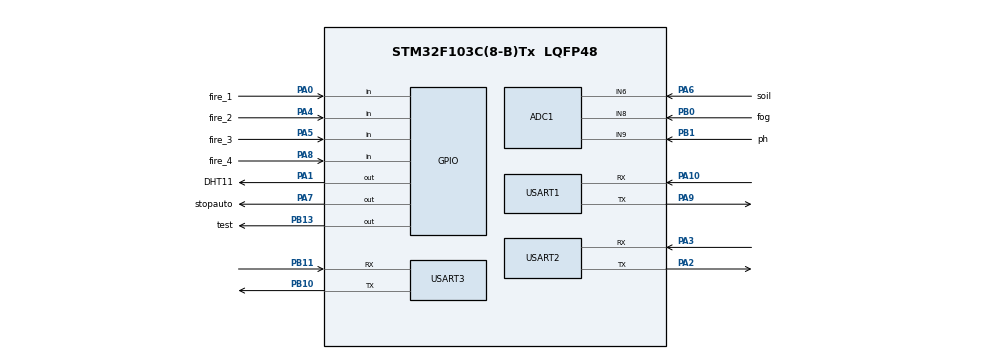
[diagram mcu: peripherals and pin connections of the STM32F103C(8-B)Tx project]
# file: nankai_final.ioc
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ADC1.Channel-0\#ChannelRegularConversion=ADC_CHANNEL_9
ADC1.NbrOfConversionFlag=1
ADC1.Rank-0\#ChannelRegularConversion=1
ADC1.SamplingTime-0\#ChannelRegularConversion=ADC_SAMPLETIME_1CYCLE_5
ADC1.master=1
Mcu.Family=STM32F1
Mcu.Name=STM32F103C(8-B)Tx
Mcu.Package=LQFP48
NVIC.PriorityGroup=NVIC_PRIORITYGROUP_4
NVIC.RCC_IRQn=true\:0\:0\:false\:false\:true\:true\:false\:true
NVIC.USART1_IRQn=true\:0\:0\:false\:false\:true\:true\:true\:true
NVIC.USART2_IRQn=true\:0\:0\:false\:false\:true\:true\:true\:true
PA0-WKUP.GPIO_Label=fire_1
PA0-WKUP.Signal=GPIO_Input
PA1.GPIO_Label=DHT11
PA1.Signal=GPIO_Output
PA10.Mode=Asynchronous
PA10.Signal=USART1_RX
PA13.Mode=Serial_Wire
PA13.Signal=SYS_JTMS-SWDIO
PA14.Mode=Serial_Wire
PA14.Signal=SYS_JTCK-SWCLK
PA2.Mode=Asynchronous
PA2.Signal=USART2_TX
PA3.Mode=Asynchronous
PA3.Signal=USART2_RX
PA4.GPIO_Label=fire_2
PA4.Signal=GPIO_Input
PA5.GPIO_Label=fire_3
PA5.Signal=GPIO_Input
PA6.GPIO_Label=soil
PA6.Signal=ADCx_IN6
PA7.GPIO_Label=stopauto
PA7.Signal=GPIO_Output
PA8.GPIO_Label=fire_4
PA8.Signal=GPIO_Input
PA9.Mode=Asynchronous
PA9.Signal=USART1_TX
PB0.GPIO_Label=fog
PB0.Signal=ADCx_IN8
PB1.GPIO_Label=ph
PB1.Signal=ADCx_IN9
PB10.Mode=Asynchronous
PB10.Signal=USART3_TX
PB11.Mode=Asynchronous
PB11.Signal=USART3_RX
PB13.GPIO_Label=test
PB13.Signal=GPIO_Output
PD0-OSC_IN.Mode=HSE-External-Oscillator
PD0-OSC_IN.Signal=RCC_OSC_IN
PD1-OSC_OUT.Mode=HSE-External-Oscillator
PD1-OSC_OUT.Signal=RCC_OSC_OUT
ProjectManager.HeapSize=0x200
ProjectManager.StackSize=0x400
ProjectManager.TargetToolchain=MDK-ARM V5
RCC.APB1Freq_Value=8000000
RCC.APB2Freq_Value=8000000
SH.ADCx_IN6.0=ADC1_IN6,IN6
SH.ADCx_IN8.0=ADC1_IN8,IN8
SH.ADCx_IN9.0=ADC1_IN9,IN9
USART1.VirtualMode=VM_ASYNC
USART2.VirtualMode=VM_ASYNC
USART3.VirtualMode=VM_ASYNC
board=custom

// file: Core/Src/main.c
/* USER CODE BEGIN Header */
/**
  ******************************************************************************
  * @file           : main.c
  * @brief          : Main program body
  ******************************************************************************
  * @attention
  *
  * Copyright (c) 2025 STMicroelectronics.
  * All rights reserved.
  *
  * This software is licensed under terms that can be found in the LICENSE file
  * in the root directory of this software component.
  * If no LICENSE file comes with this software, it is provided AS-IS.
  *
  ******************************************************************************
  */
/* USER CODE END Header */
#include "main.h"
#include "adc.h"
#include "usart.h"
#include "gpio.h"

/* USER CODE BEGIN Includes */
#include "sensors.h"
#include <stdio.h>
#include <string.h>
/* USER CODE END Includes */

/* USER CODE BEGIN PV */
uint32_t sensorTimer = 0; // 传感器定时器计数
/* USER CODE END PV */

void SystemClock_Config(void);

int main(void)
{

  /* MCU Configuration--------------------------------------------------------*/

  /* Reset of all peripherals, Initializes the Flash interface and the Systick. */
  HAL_Init();

  /* Configure the system clock */
  SystemClock_Config();

  /* Initialize all configured peripherals */
  MX_GPIO_Init();
  MX_ADC1_Init();
  MX_USART1_UART_Init();
  MX_USART2_UART_Init();
  MX_USART3_UART_Init();
  /* USER CODE BEGIN 2 */

  // 初始化传感器
  Sensors_Init();

  // 发�?�启动消�?
  char startup_msg[] = "STM32 Sensor System Started\r\n";
  HAL_UART_Transmit(&huart1, (uint8_t*)startup_msg, strlen(startup_msg), 100);

  // 获取初始传感器数据并发�??
  Sensors_SendDataToUSART3();

  // 初始化定时器
  sensorTimer = HAL_GetTick();

  /* USER CODE END 2 */

  /* Infinite loop */
  while (1)
  {

    /* USER CODE BEGIN 3 */

    // �?1000ms(1�?)读取�?次传感器数据并发�?
    if (HAL_GetTick() - sensorTimer >= 1000)
    {
      // 获取并发送所有传感器数据
      Sensors_TimerHandler();

      // 更新定时�?
      sensorTimer = HAL_GetTick();
    }

  }
  /* USER CODE END 3 */
}

void SystemClock_Config(void)
{
  RCC_OscInitTypeDef RCC_OscInitStruct = {0};
  RCC_ClkInitTypeDef RCC_ClkInitStruct = {0};
  RCC_PeriphCLKInitTypeDef PeriphClkInit = {0};

  /** Initializes the RCC Oscillators according to the specified parameters
  * in the RCC_OscInitTypeDef structure.
  */
  RCC_OscInitStruct.OscillatorType = RCC_OSCILLATORTYPE_HSI;
  RCC_OscInitStruct.HSIState = RCC_HSI_ON;
  RCC_OscInitStruct.HSICalibrationValue = RCC_HSICALIBRATION_DEFAULT;
  RCC_OscInitStruct.PLL.PLLState = RCC_PLL_NONE;
  if (HAL_RCC_OscConfig(&RCC_OscInitStruct) != HAL_OK)
  {
    Error_Handler();
  }

  /** Initializes the CPU, AHB and APB buses clocks
  */
  RCC_ClkInitStruct.ClockType = RCC_CLOCKTYPE_HCLK|RCC_CLOCKTYPE_SYSCLK
                              |RCC_CLOCKTYPE_PCLK1|RCC_CLOCKTYPE_PCLK2;
  RCC_ClkInitStruct.SYSCLKSource = RCC_SYSCLKSOURCE_HSI;
  RCC_ClkInitStruct.AHBCLKDivider = RCC_SYSCLK_DIV1;
  RCC_ClkInitStruct.APB1CLKDivider = RCC_HCLK_DIV1;
  RCC_ClkInitStruct.APB2CLKDivider = RCC_HCLK_DIV1;

  if (HAL_RCC_ClockConfig(&RCC_ClkInitStruct, FLASH_LATENCY_0) != HAL_OK)
  {
    Error_Handler();
  }
  PeriphClkInit.PeriphClockSelection = RCC_PERIPHCLK_ADC;
  PeriphClkInit.AdcClockSelection = RCC_ADCPCLK2_DIV2;
  if (HAL_RCCEx_PeriphCLKConfig(&PeriphClkInit) != HAL_OK)
  {
    Error_Handler();
  }
}

void Error_Handler(void)
{
  __disable_irq();
  while (1)
  {
  }
}
